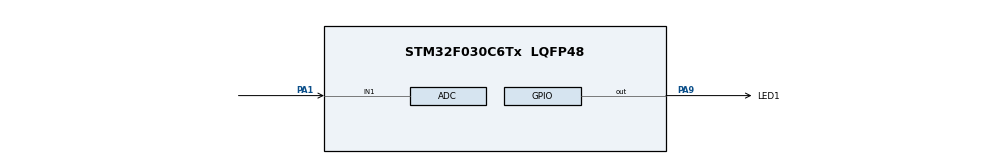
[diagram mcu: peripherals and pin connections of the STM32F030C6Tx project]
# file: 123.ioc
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Dma.ADC.0.Direction=DMA_PERIPH_TO_MEMORY
Dma.ADC.0.Instance=DMA1_Channel1
Dma.ADC.0.MemDataAlignment=DMA_MDATAALIGN_HALFWORD
Dma.ADC.0.MemInc=DMA_MINC_ENABLE
Dma.ADC.0.Mode=DMA_NORMAL
Dma.ADC.0.PeriphDataAlignment=DMA_PDATAALIGN_HALFWORD
Dma.ADC.0.PeriphInc=DMA_PINC_DISABLE
Dma.ADC.0.Priority=DMA_PRIORITY_LOW
Dma.Request0=ADC
Mcu.Family=STM32F0
Mcu.Name=STM32F030C6Tx
Mcu.Package=LQFP48
NVIC.DMA1_Channel1_IRQn=true\:0\:0\:false\:false\:true\:false\:true\:true
PA1.Mode=IN1
PA1.Signal=ADC_IN1
PA9.GPIO_Label=LED1
PA9.PinState=GPIO_PIN_RESET
PA9.Signal=GPIO_Output
ProjectManager.HeapSize=0x200
ProjectManager.StackSize=0x400
ProjectManager.TargetToolchain=STM32CubeIDE
board=custom

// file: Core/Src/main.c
/* USER CODE BEGIN Header */
/**
  ******************************************************************************
  * @file           : main.c
  * @brief          : Main program body
  ******************************************************************************
  * @attention
  *
  * Copyright (c) 2023 STMicroelectronics.
  * All rights reserved.
  *
  * This software is licensed under terms that can be found in the LICENSE file
  * in the root directory of this software component.
  * If no LICENSE file comes with this software, it is provided AS-IS.
  *
  ******************************************************************************
  */
/* USER CODE END Header */
#include "main.h"

/* USER CODE BEGIN PD */
#define ADC_REFERENCE_VOLTAGE                                           1.2
#define ADC_MAX                                                         0xFFF

/* USER CODE END PD */

ADC_HandleTypeDef hadc;
DMA_HandleTypeDef hdma_adc;

/* USER CODE BEGIN PV */
float mcuVoltage = 0;
uint16_t adcData = 0;
/* USER CODE END PV */

void SystemClock_Config(void);
static void MX_GPIO_Init(void);
static void MX_DMA_Init(void);
static void MX_ADC_Init(void);

int main(void)
{

  /* MCU Configuration--------------------------------------------------------*/

  /* Reset of all peripherals, Initializes the Flash interface and the Systick. */
  HAL_Init();

  /* Configure the system clock */
  SystemClock_Config();

  /* Initialize all configured peripherals */
  MX_GPIO_Init();
  MX_DMA_Init();
  MX_ADC_Init();

  /* Infinite loop */
  /* USER CODE BEGIN WHILE */
  while (1)
  {
	  /*HAL_GPIO_WritePin(LED1_GPIO_Port,LED1_Pin,GPIO_PIN_SET);
	  HAL_Delay(500);
	  HAL_GPIO_WritePin(LED1_GPIO_Port,LED1_Pin,GPIO_PIN_RESET);*/
	  mcuVoltage = ADC_MAX * ADC_REFERENCE_VOLTAGE / adcData;

	  if (mcuVoltage < 3) {
		  HAL_GPIO_WritePin(LED1_GPIO_Port,LED1_Pin,GPIO_PIN_SET);
	  } else {
		  HAL_GPIO_WritePin(LED1_GPIO_Port,LED1_Pin,GPIO_PIN_RESET);
	  }

    /* USER CODE END WHILE */

  }
}

void SystemClock_Config(void)
{
  RCC_OscInitTypeDef RCC_OscInitStruct = {0};
  RCC_ClkInitTypeDef RCC_ClkInitStruct = {0};

  /** Initializes the RCC Oscillators according to the specified parameters
  * in the RCC_OscInitTypeDef structure.
  */
  RCC_OscInitStruct.OscillatorType = RCC_OSCILLATORTYPE_HSI|RCC_OSCILLATORTYPE_HSI14;
  RCC_OscInitStruct.HSIState = RCC_HSI_ON;
  RCC_OscInitStruct.HSI14State = RCC_HSI14_ON;
  RCC_OscInitStruct.HSICalibrationValue = RCC_HSICALIBRATION_DEFAULT;
  RCC_OscInitStruct.HSI14CalibrationValue = 16;
  RCC_OscInitStruct.PLL.PLLState = RCC_PLL_NONE;
  if (HAL_RCC_OscConfig(&RCC_OscInitStruct) != HAL_OK)
  {
    Error_Handler();
  }

  /** Initializes the CPU, AHB and APB buses clocks
  */
  RCC_ClkInitStruct.ClockType = RCC_CLOCKTYPE_HCLK|RCC_CLOCKTYPE_SYSCLK
                              |RCC_CLOCKTYPE_PCLK1;
  RCC_ClkInitStruct.SYSCLKSource = RCC_SYSCLKSOURCE_HSI;
  RCC_ClkInitStruct.AHBCLKDivider = RCC_SYSCLK_DIV1;
  RCC_ClkInitStruct.APB1CLKDivider = RCC_HCLK_DIV1;

  if (HAL_RCC_ClockConfig(&RCC_ClkInitStruct, FLASH_LATENCY_0) != HAL_OK)
  {
    Error_Handler();
  }
}

static void MX_ADC_Init(void)
{

  ADC_ChannelConfTypeDef sConfig = {0};

  /** Configure the global features of the ADC (Clock, Resolution, Data Alignment and number of conversion)
  */
  hadc.Instance = ADC1;
  hadc.Init.ClockPrescaler = ADC_CLOCK_ASYNC_DIV1;
  hadc.Init.Resolution = ADC_RESOLUTION_12B;
  hadc.Init.DataAlign = ADC_DATAALIGN_RIGHT;
  hadc.Init.ScanConvMode = ADC_SCAN_DIRECTION_FORWARD;
  hadc.Init.EOCSelection = ADC_EOC_SINGLE_CONV;
  hadc.Init.LowPowerAutoWait = DISABLE;
  hadc.Init.LowPowerAutoPowerOff = DISABLE;
  hadc.Init.ContinuousConvMode = DISABLE;
  hadc.Init.DiscontinuousConvMode = DISABLE;
  hadc.Init.ExternalTrigConv = ADC_SOFTWARE_START;
  hadc.Init.ExternalTrigConvEdge = ADC_EXTERNALTRIGCONVEDGE_NONE;
  hadc.Init.DMAContinuousRequests = DISABLE;
  hadc.Init.Overrun = ADC_OVR_DATA_PRESERVED;
  if (HAL_ADC_Init(&hadc) != HAL_OK)
  {
    Error_Handler();
  }

  /** Configure for the selected ADC regular channel to be converted.
  */
  sConfig.Channel = ADC_CHANNEL_1;
  sConfig.Rank = ADC_RANK_CHANNEL_NUMBER;
  sConfig.SamplingTime = ADC_SAMPLETIME_1CYCLE_5;
  if (HAL_ADC_ConfigChannel(&hadc, &sConfig) != HAL_OK)
  {
    Error_Handler();
  }

}

static void MX_DMA_Init(void)
{

  /* DMA controller clock enable */
  __HAL_RCC_DMA1_CLK_ENABLE();

  /* DMA interrupt init */
  /* DMA1_Channel1_IRQn interrupt configuration */
  HAL_NVIC_SetPriority(DMA1_Channel1_IRQn, 0, 0);
  HAL_NVIC_EnableIRQ(DMA1_Channel1_IRQn);

}

static void MX_GPIO_Init(void)
{
  GPIO_InitTypeDef GPIO_InitStruct = {0};

  /* GPIO Ports Clock Enable */
  __HAL_RCC_GPIOA_CLK_ENABLE();

  /*Configure GPIO pin Output Level */
  HAL_GPIO_WritePin(LED1_GPIO_Port, LED1_Pin, GPIO_PIN_RESET);

  /*Configure GPIO pin : LED1_Pin */
  GPIO_InitStruct.Pin = LED1_Pin;
  GPIO_InitStruct.Mode = GPIO_MODE_OUTPUT_PP;
  GPIO_InitStruct.Pull = GPIO_NOPULL;
  GPIO_InitStruct.Speed = GPIO_SPEED_FREQ_LOW;
  HAL_GPIO_Init(LED1_GPIO_Port, &GPIO_InitStruct);

}

void Error_Handler(void)
{
  __disable_irq();
  while (1)
  {
  }
}
